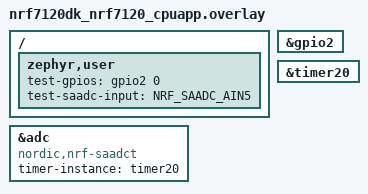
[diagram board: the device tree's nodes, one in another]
/*
 * Copyright (c) 2026 Nordic Semiconductor ASA
 *
 * SPDX-License-Identifier: LicenseRef-Nordic-5-Clause
 */

/*
 * Test requires loopback between P0.06 and P2.00
 */

/ {
	zephyr,user {
		test-gpios = <&gpio2 0 GPIO_ACTIVE_HIGH>;
		test-saadc-input = <NRF_SAADC_AIN5>; /* P0.06 */
	};
};

&adc {
	compatible = "nordic,nrf-saadct";
	status = "okay";
	timer-instance = <&timer20>;
	#address-cells = <1>;
	#size-cells = <0>;
};

&gpio2 {
	status = "okay";
};

&timer20 {
	status = "okay";
};
